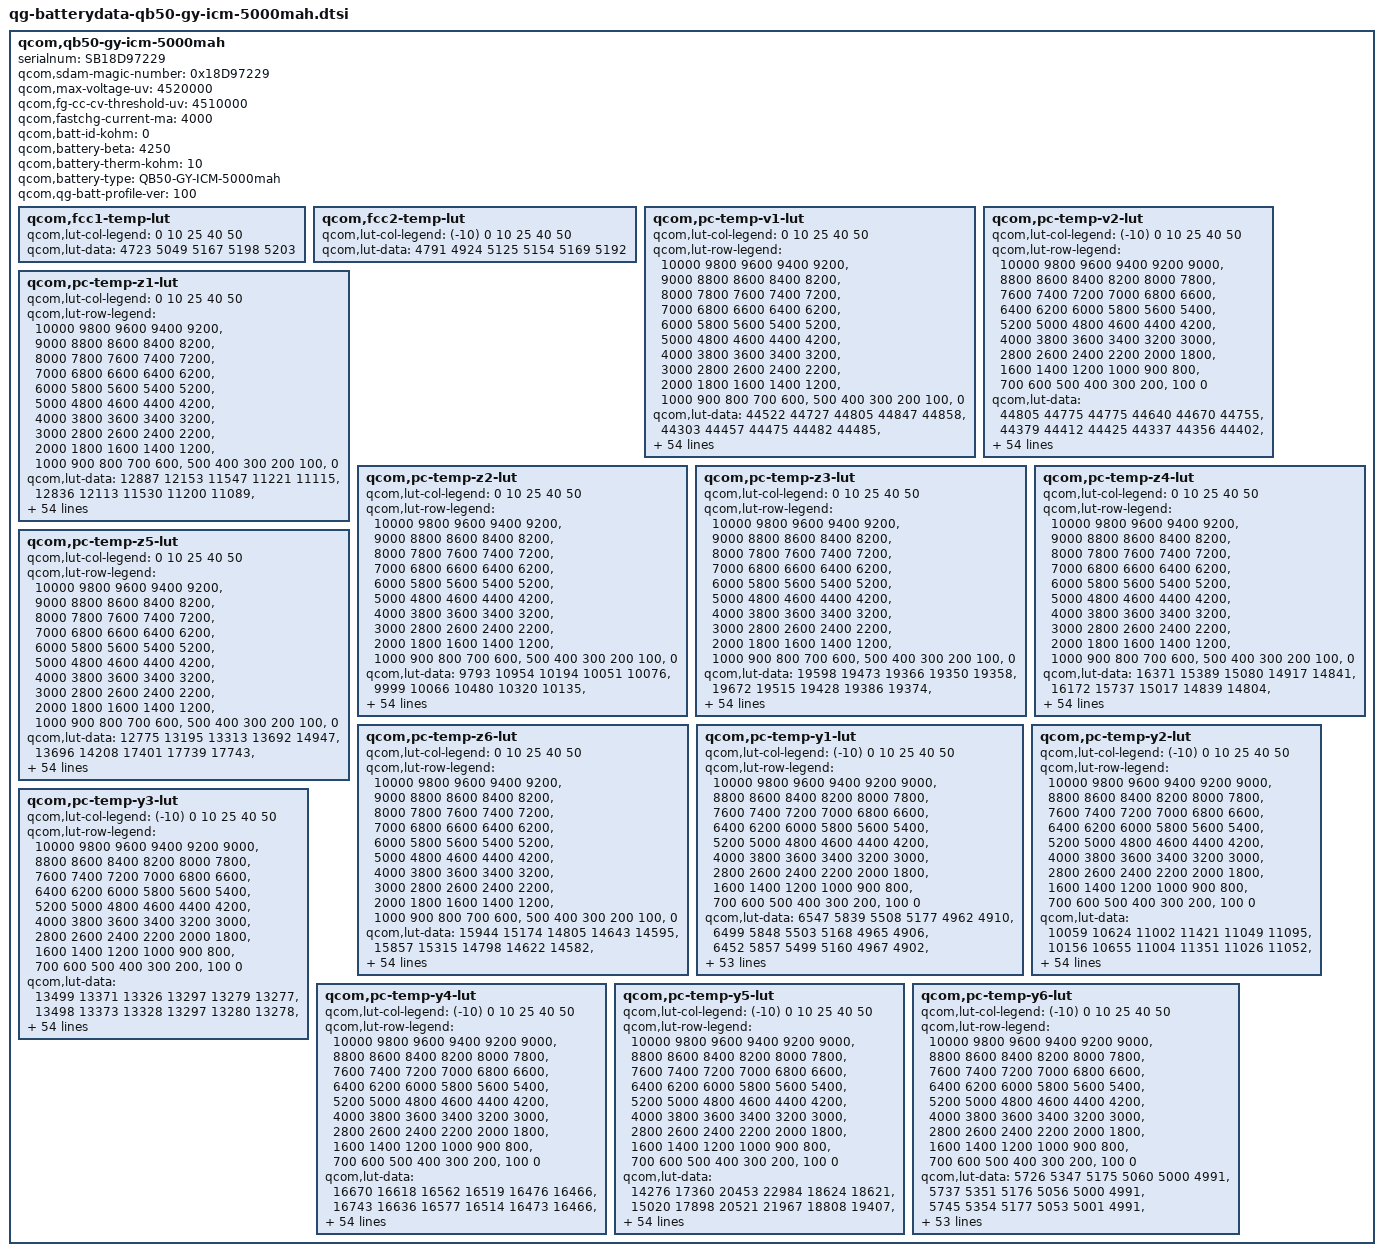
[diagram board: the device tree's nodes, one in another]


qcom,qb50-gy-icm-5000mah {
    /* 6658361_Heyuan_P652A_5000mAH_averaged_MasterSlave_Jun12th2023 */
    serialnum = "SB18D97229";
    qcom,sdam-magic-number = <0x18D97229>;
    qcom,max-voltage-uv = <4520000>;
    qcom,fg-cc-cv-threshold-uv = <4510000>;
    qcom,fastchg-current-ma = <4000>;
    qcom,batt-id-kohm = <0>;
    qcom,battery-beta = <4250>;
    qcom,battery-therm-kohm = <10>;
    qcom,battery-type = "QB50-GY-ICM-5000mah";
    qcom,qg-batt-profile-ver = <100>;

	qcom,fcc1-temp-lut {
		qcom,lut-col-legend = <0 10 25 40 50>;
		qcom,lut-data = <4723 5049 5167 5198 5203>;
	};

	qcom,fcc2-temp-lut {
		qcom,lut-col-legend = <(-10) 0 10 25 40 50>;
		qcom,lut-data = <4791 4924 5125 5154 5169 5192>;
	};

	qcom,pc-temp-v1-lut {
		qcom,lut-col-legend = <0 10 25 40 50>;
		qcom,lut-row-legend = <10000 9800 9600 9400 9200>,
			<9000 8800 8600 8400 8200>,
			<8000 7800 7600 7400 7200>,
			<7000 6800 6600 6400 6200>,
			<6000 5800 5600 5400 5200>,
			<5000 4800 4600 4400 4200>,
			<4000 3800 3600 3400 3200>,
			<3000 2800 2600 2400 2200>,
			<2000 1800 1600 1400 1200>,
			<1000 900 800 700 600>,
			<500 400 300 200 100>,
			<0>;
		qcom,lut-data = <44522 44727 44805 44847 44858>,
			<44303 44457 44475 44482 44485>,
			<44087 44233 44234 44237 44232>,
			<43876 44018 44024 44024 44019>,
			<43671 43803 43815 43814 43814>,
			<43461 43588 43593 43597 43600>,
			<43237 43361 43364 43374 43380>,
			<43005 43123 43127 43142 43151>,
			<42770 42878 42881 42899 42910>,
			<42528 42627 42631 42649 42662>,
			<42287 42372 42375 42396 42411>,
			<42052 42124 42119 42140 42157>,
			<41822 41878 41872 41890 41907>,
			<41596 41638 41633 41646 41660>,
			<41374 41402 41397 41408 41419>,
			<41157 41173 41160 41174 41183>,
			<40949 40956 40932 40947 40955>,
			<40748 40750 40719 40731 40737>,
			<40555 40550 40519 40523 40530>,
			<40367 40353 40326 40327 40332>,
			<40184 40161 40149 40153 40155>,
			<40008 39977 39953 39966 39969>,
			<39842 39801 39686 39701 39709>,
			<39679 39595 39399 39394 39406>,
			<39507 39302 39189 39188 39202>,
			<39328 39029 39021 39050 39069>,
			<39150 38883 38886 38932 38949>,
			<38970 38784 38781 38820 38819>,
			<38792 38693 38690 38717 38695>,
			<38661 38605 38598 38615 38588>,
			<38576 38526 38511 38517 38494>,
			<38507 38452 38430 38426 38408>,
			<38446 38383 38354 38345 38328>,
			<38389 38322 38284 38268 38252>,
			<38340 38268 38222 38198 38179>,
			<38295 38220 38164 38134 38109>,
			<38254 38178 38111 38069 38037>,
			<38215 38139 38063 38007 37964>,
			<38181 38090 38005 37936 37881>,
			<38144 38025 37922 37839 37776>,
			<38092 37944 37818 37726 37654>,
			<38021 37836 37703 37608 37531>,
			<37924 37701 37566 37481 37400>,
			<37788 37548 37403 37323 37231>,
			<37660 37380 37239 37167 37075>,
			<37496 37223 37118 37065 36992>,
			<37406 37171 37085 37031 36960>,
			<37315 37137 37057 37009 36935>,
			<37231 37101 37035 36989 36914>,
			<37158 37067 37000 36947 36867>,
			<37098 37027 36838 36740 36632>,
			<37041 36870 36419 36308 36189>,
			<36978 36431 35820 35721 35598>,
			<36882 35734 34989 34922 34783>,
			<36533 34686 33673 33672 33515>,
			<30000 30000 30000 30000 30000>;
	};

	qcom,pc-temp-v2-lut {
		qcom,lut-col-legend = <(-10) 0 10 25 40 50>;
		qcom,lut-row-legend = <10000 9800 9600 9400 9200 9000>,
			<8800 8600 8400 8200 8000 7800>,
			<7600 7400 7200 7000 6800 6600>,
			<6400 6200 6000 5800 5600 5400>,
			<5200 5000 4800 4600 4400 4200>,
			<4000 3800 3600 3400 3200 3000>,
			<2800 2600 2400 2200 2000 1800>,
			<1600 1400 1200 1000 900 800>,
			<700 600 500 400 300 200>,
			<100 0>;
		qcom,lut-data = <44805 44775 44775 44640 44670 44755>,
			<44379 44412 44425 44337 44356 44402>,
			<44020 44101 44121 44063 44075 44097>,
			<43748 43854 43874 43824 43834 43852>,
			<43548 43662 43673 43617 43628 43652>,
			<43364 43474 43469 43404 43416 43446>,
			<43161 43265 43244 43176 43189 43222>,
			<42955 43047 43012 42940 42954 42992>,
			<42744 42823 42773 42697 42711 42752>,
			<42527 42589 42525 42445 42460 42504>,
			<42302 42353 42277 42194 42209 42254>,
			<42073 42118 42027 41942 41958 42003>,
			<41838 41884 41777 41692 41709 41753>,
			<41596 41653 41533 41450 41467 41507>,
			<41342 41430 41293 41213 41230 41266>,
			<41080 41205 41061 40982 41000 41034>,
			<40827 40973 40839 40756 40774 40809>,
			<40579 40735 40620 40539 40557 40592>,
			<40338 40488 40404 40339 40352 40383>,
			<40103 40221 40186 40140 40152 40180>,
			<39873 39959 39941 39920 39961 39991>,
			<39656 39722 39662 39679 39776 39810>,
			<39452 39502 39405 39443 39566 39597>,
			<39257 39299 39188 39207 39293 39317>,
			<39069 39111 38994 38993 39037 39064>,
			<38888 38938 38828 38830 38865 38891>,
			<38718 38778 38682 38694 38728 38749>,
			<38556 38632 38548 38570 38604 38620>,
			<38406 38496 38420 38456 38491 38503>,
			<38287 38365 38302 38350 38388 38396>,
			<38194 38244 38193 38253 38295 38300>,
			<38114 38135 38092 38164 38210 38212>,
			<38038 38035 38001 38083 38132 38133>,
			<37969 37950 37918 38010 38062 38060>,
			<37901 37884 37845 37939 37987 37979>,
			<37832 37826 37785 37871 37904 37885>,
			<37765 37766 37732 37802 37815 37785>,
			<37696 37707 37677 37724 37717 37672>,
			<37627 37643 37621 37639 37611 37555>,
			<37556 37575 37554 37549 37509 37450>,
			<37482 37502 37451 37453 37414 37357>,
			<37406 37419 37323 37345 37311 37256>,
			<37328 37327 37181 37219 37192 37141>,
			<37249 37221 37022 37065 37040 36985>,
			<37165 37099 36844 36913 36915 36850>,
			<37075 36958 36683 36847 36869 36807>,
			<37025 36881 36623 36821 36857 36793>,
			<36968 36792 36543 36800 36843 36780>,
			<36911 36693 36413 36764 36816 36750>,
			<36858 36592 36252 36695 36741 36650>,
			<36801 36491 36007 36462 36452 36322>,
			<36629 36358 35443 35949 35930 35787>,
			<36422 36010 34906 35232 35242 35073>,
			<36366 35980 34417 34248 34233 34047>,
			<36694 36128 33625 32780 32977 32613>,
			<37268 36260 32241 29173 28356 28386>;
	};

	qcom,pc-temp-z1-lut {
		qcom,lut-col-legend = <0 10 25 40 50>;
		qcom,lut-row-legend = <10000 9800 9600 9400 9200>,
			<9000 8800 8600 8400 8200>,
			<8000 7800 7600 7400 7200>,
			<7000 6800 6600 6400 6200>,
			<6000 5800 5600 5400 5200>,
			<5000 4800 4600 4400 4200>,
			<4000 3800 3600 3400 3200>,
			<3000 2800 2600 2400 2200>,
			<2000 1800 1600 1400 1200>,
			<1000 900 800 700 600>,
			<500 400 300 200 100>,
			<0>;
		qcom,lut-data = <12887 12153 11547 11221 11115>,
			<12836 12113 11530 11200 11089>,
			<12794 12084 11502 11179 11076>,
			<12761 12059 11485 11167 11067>,
			<12733 12038 11470 11157 11060>,
			<12715 12018 11455 11147 11053>,
			<12706 11996 11441 11137 11046>,
			<12700 11970 11425 11129 11041>,
			<12687 11946 11409 11122 11037>,
			<12654 11924 11397 11116 11033>,
			<12614 11906 11389 11111 11030>,
			<12582 11895 11383 11108 11027>,
			<12548 11888 11379 11105 11024>,
			<12524 11882 11375 11103 11023>,
			<12510 11874 11373 11101 11022>,
			<12501 11868 11373 11100 11020>,
			<12494 11868 11372 11098 11019>,
			<12490 11871 11371 11098 11019>,
			<12487 11873 11369 11097 11019>,
			<12482 11872 11369 11097 11019>,
			<12475 11872 11372 11098 11019>,
			<12471 11874 11374 11099 11020>,
			<12481 11882 11374 11099 11019>,
			<12496 11889 11373 11099 11019>,
			<12501 11892 11374 11099 11018>,
			<12499 11896 11377 11101 11019>,
			<12498 11901 11381 11104 11021>,
			<12506 11908 11386 11107 11023>,
			<12523 11915 11391 11111 11027>,
			<12531 11921 11396 11115 11030>,
			<12529 11926 11401 11118 11033>,
			<12526 11932 11407 11122 11035>,
			<12529 11937 11414 11127 11038>,
			<12540 11944 11420 11132 11041>,
			<12550 11956 11424 11137 11045>,
			<12557 11968 11427 11143 11050>,
			<12565 11977 11433 11148 11054>,
			<12574 11984 11441 11152 11057>,
			<12588 11994 11449 11157 11061>,
			<12604 12008 11456 11162 11064>,
			<12625 12024 11462 11168 11068>,
			<12658 12043 11469 11173 11072>,
			<12688 12061 11477 11178 11075>,
			<12719 12068 11487 11184 11079>,
			<12710 12088 11501 11190 11082>,
			<12731 12105 11509 11196 11087>,
			<12742 12105 11509 11195 11086>,
			<12759 12099 11509 11197 11087>,
			<12759 12101 11512 11201 11090>,
			<12740 12105 11520 11206 11095>,
			<12732 12125 11523 11213 11100>,
			<12733 12134 11535 11220 11107>,
			<12740 12160 11541 11231 11117>,
			<12743 12179 11565 11246 11130>,
			<12743 12179 11565 11246 11130>,
			<12743 12179 11565 11246 11130>;
	};

	qcom,pc-temp-z2-lut {
		qcom,lut-col-legend = <0 10 25 40 50>;
		qcom,lut-row-legend = <10000 9800 9600 9400 9200>,
			<9000 8800 8600 8400 8200>,
			<8000 7800 7600 7400 7200>,
			<7000 6800 6600 6400 6200>,
			<6000 5800 5600 5400 5200>,
			<5000 4800 4600 4400 4200>,
			<4000 3800 3600 3400 3200>,
			<3000 2800 2600 2400 2200>,
			<2000 1800 1600 1400 1200>,
			<1000 900 800 700 600>,
			<500 400 300 200 100>,
			<0>;
		qcom,lut-data = <9793 10954 10194 10051 10076>,
			<9999 10066 10480 10320 10135>,
			<10135 10250 10606 10491 10349>,
			<10166 10372 10550 10471 10371>,
			<10176 10357 10483 10436 10382>,
			<10180 10323 10439 10396 10368>,
			<10178 10292 10401 10346 10311>,
			<10172 10260 10356 10302 10267>,
			<10165 10234 10301 10260 10240>,
			<10157 10212 10277 10235 10225>,
			<10146 10197 10281 10244 10228>,
			<10133 10197 10293 10263 10236>,
			<10117 10208 10473 10263 10241>,
			<10105 10222 11000 10232 10244>,
			<10100 10233 11182 10213 10246>,
			<10096 10248 10746 10237 10262>,
			<10097 10363 10337 10270 10285>,
			<10108 10707 10653 10261 10283>,
			<10123 10867 11354 10219 10252>,
			<10134 10639 11448 10200 10236>,
			<10144 10369 10824 10203 10224>,
			<10155 10348 10395 10215 10226>,
			<10167 10373 10487 10372 10376>,
			<10181 10400 10624 10678 10664>,
			<10199 10433 10610 10709 10705>,
			<10222 10458 10472 10418 10459>,
			<10246 10452 10405 10228 10290>,
			<10266 10430 10413 10243 10493>,
			<10286 10418 10425 10277 10790>,
			<10293 10414 10438 10343 10777>,
			<10288 10411 10460 10466 10553>,
			<10281 10408 10479 10511 10369>,
			<10278 10404 10495 10460 10243>,
			<10276 10403 10505 10391 10167>,
			<10275 10404 10509 10331 10163>,
			<10273 10406 10510 10267 10169>,
			<10272 10410 10510 10255 10187>,
			<10270 10414 10510 10273 10255>,
			<10265 10415 10514 10301 10328>,
			<10258 10409 10544 10395 10390>,
			<10245 10398 10577 10506 10438>,
			<10224 10381 10577 10506 10435>,
			<10204 10356 10563 10454 10406>,
			<10183 10315 10537 10418 10488>,
			<9927 10305 10524 10401 10565>,
			<9862 10299 10526 10406 10379>,
			<9827 10170 10398 10377 10354>,
			<9803 10110 10326 10377 10348>,
			<9775 10113 10361 10398 10377>,
			<9756 10100 10385 10460 10458>,
			<9748 10101 10377 10409 10383>,
			<9737 10032 10349 10237 10164>,
			<9694 9911 10186 10167 10088>,
			<9683 10032 10136 10104 10023>,
			<9683 10032 10136 10104 10023>,
			<9683 10032 10136 10104 10023>;
	};

	qcom,pc-temp-z3-lut {
		qcom,lut-col-legend = <0 10 25 40 50>;
		qcom,lut-row-legend = <10000 9800 9600 9400 9200>,
			<9000 8800 8600 8400 8200>,
			<8000 7800 7600 7400 7200>,
			<7000 6800 6600 6400 6200>,
			<6000 5800 5600 5400 5200>,
			<5000 4800 4600 4400 4200>,
			<4000 3800 3600 3400 3200>,
			<3000 2800 2600 2400 2200>,
			<2000 1800 1600 1400 1200>,
			<1000 900 800 700 600>,
			<500 400 300 200 100>,
			<0>;
		qcom,lut-data = <19598 19473 19366 19350 19358>,
			<19672 19515 19428 19386 19374>,
			<19720 19556 19468 19414 19398>,
			<19726 19578 19470 19421 19405>,
			<19724 19581 19472 19425 19408>,
			<19722 19582 19476 19428 19411>,
			<19716 19581 19481 19430 19414>,
			<19706 19576 19481 19431 19415>,
			<19703 19572 19478 19428 19413>,
			<19703 19570 19473 19423 19410>,
			<19703 19569 19466 19421 19408>,
			<19700 19563 19460 19419 19406>,
			<19692 19548 19465 19415 19404>,
			<19685 19536 19480 19408 19400>,
			<19683 19529 19485 19402 19397>,
			<19681 19524 19455 19398 19394>,
			<19677 19530 19428 19395 19391>,
			<19665 19553 19435 19391 19386>,
			<19652 19564 19453 19387 19381>,
			<19647 19537 19453 19382 19375>,
			<19644 19506 19423 19374 19369>,
			<19641 19503 19402 19368 19364>,
			<19638 19504 19417 19374 19368>,
			<19635 19507 19440 19389 19377>,
			<19636 19521 19439 19388 19377>,
			<19643 19536 19423 19365 19353>,
			<19652 19534 19411 19349 19337>,
			<19656 19525 19405 19350 19372>,
			<19659 19518 19401 19351 19422>,
			<19660 19514 19402 19359 19427>,
			<19654 19511 19405 19384 19416>,
			<19646 19512 19409 19395 19405>,
			<19641 19514 19416 19396 19395>,
			<19637 19515 19422 19395 19385>,
			<19634 19516 19423 19390 19374>,
			<19633 19516 19424 19380 19364>,
			<19632 19516 19423 19372 19356>,
			<19631 19515 19417 19365 19349>,
			<19629 19513 19411 19361 19346>,
			<19627 19508 19409 19362 19346>,
			<19622 19503 19407 19362 19346>,
			<19612 19500 19404 19362 19347>,
			<19601 19497 19401 19361 19351>,
			<19588 19490 19397 19360 19359>,
			<19402 19466 19390 19358 19364>,
			<19391 19445 19381 19348 19348>,
			<19394 19422 19371 19345 19342>,
			<19399 19356 19365 19337 19335>,
			<19400 19340 19349 19333 19328>,
			<19397 19331 19337 19326 19317>,
			<19389 19321 19339 19339 19333>,
			<19377 19333 19336 19362 19356>,
			<19382 19348 19358 19366 19356>,
			<19420 19503 19394 19357 19361>,
			<19420 19503 19394 19357 19361>,
			<19420 19503 19394 19357 19361>;
	};

	qcom,pc-temp-z4-lut {
		qcom,lut-col-legend = <0 10 25 40 50>;
		qcom,lut-row-legend = <10000 9800 9600 9400 9200>,
			<9000 8800 8600 8400 8200>,
			<8000 7800 7600 7400 7200>,
			<7000 6800 6600 6400 6200>,
			<6000 5800 5600 5400 5200>,
			<5000 4800 4600 4400 4200>,
			<4000 3800 3600 3400 3200>,
			<3000 2800 2600 2400 2200>,
			<2000 1800 1600 1400 1200>,
			<1000 900 800 700 600>,
			<500 400 300 200 100>,
			<0>;
		qcom,lut-data = <16371 15389 15080 14917 14841>,
			<16172 15737 15017 14839 14804>,
			<15980 15520 15159 14918 14869>,
			<15790 15297 15059 14887 14848>,
			<15597 15166 14950 14836 14808>,
			<15437 15060 14893 14805 14783>,
			<15320 14986 14848 14781 14764>,
			<15224 14931 14814 14761 14748>,
			<15143 14887 14787 14742 14733>,
			<15072 14849 14765 14728 14722>,
			<15012 14818 14750 14720 14716>,
			<14967 14796 14735 14714 14712>,
			<14931 14779 14706 14709 14708>,
			<14899 14766 14662 14706 14704>,
			<14867 14759 14649 14702 14700>,
			<14838 14752 14677 14697 14696>,
			<14819 14729 14703 14690 14691>,
			<14807 14679 14684 14686 14688>,
			<14797 14657 14642 14683 14686>,
			<14788 14686 14634 14679 14683>,
			<14781 14720 14656 14675 14677>,
			<14775 14722 14687 14672 14672>,
			<14769 14717 14722 14702 14701>,
			<14765 14718 14761 14771 14770>,
			<14765 14771 14793 14806 14802>,
			<14770 14828 14823 14825 14816>,
			<14780 14830 14834 14833 14821>,
			<14801 14822 14825 14823 14774>,
			<14836 14813 14809 14803 14704>,
			<14851 14803 14794 14775 14690>,
			<14850 14792 14776 14736 14688>,
			<14849 14781 14759 14709 14686>,
			<14847 14771 14740 14694 14683>,
			<14841 14763 14725 14685 14681>,
			<14835 14755 14714 14683 14679>,
			<14828 14749 14706 14682 14677>,
			<14821 14745 14705 14681 14677>,
			<14811 14741 14704 14682 14677>,
			<14796 14737 14704 14683 14678>,
			<14777 14732 14707 14690 14687>,
			<14760 14726 14711 14700 14700>,
			<14743 14718 14709 14699 14698>,
			<14729 14707 14701 14693 14688>,
			<14718 14694 14696 14694 14687>,
			<14852 14683 14686 14691 14683>,
			<14866 14680 14664 14669 14661>,
			<14868 14706 14667 14668 14660>,
			<14870 14776 14661 14661 14654>,
			<14876 14792 14664 14642 14638>,
			<14887 14799 14666 14633 14628>,
			<14902 14809 14675 14647 14649>,
			<14923 14800 14703 14649 14657>,
			<14926 14810 14690 14653 14666>,
			<14911 14683 14671 14667 14669>,
			<14911 14683 14671 14667 14669>,
			<14911 14683 14671 14667 14669>;
	};

	qcom,pc-temp-z5-lut {
		qcom,lut-col-legend = <0 10 25 40 50>;
		qcom,lut-row-legend = <10000 9800 9600 9400 9200>,
			<9000 8800 8600 8400 8200>,
			<8000 7800 7600 7400 7200>,
			<7000 6800 6600 6400 6200>,
			<6000 5800 5600 5400 5200>,
			<5000 4800 4600 4400 4200>,
			<4000 3800 3600 3400 3200>,
			<3000 2800 2600 2400 2200>,
			<2000 1800 1600 1400 1200>,
			<1000 900 800 700 600>,
			<500 400 300 200 100>,
			<0>;
		qcom,lut-data = <12775 13195 13313 13692 14947>,
			<13696 14208 17401 17739 17743>,
			<14403 15328 16944 18315 19312>,
			<14811 16225 17364 18961 20257>,
			<15073 16791 17968 20071 21398>,
			<15320 17231 18731 20830 22265>,
			<15588 17618 19632 21465 22969>,
			<15872 17938 20162 22140 23747>,
			<16261 18333 20455 22881 24707>,
			<16912 19112 20842 23652 25656>,
			<17599 19932 21495 24623 26442>,
			<18056 20237 22582 25599 27147>,
			<18406 20367 26608 25741 27768>,
			<18851 20545 35628 25324 28334>,
			<19766 20903 38639 25063 28999>,
			<20931 21555 31015 25873 30300>,
			<21680 24978 23830 27260 31816>,
			<22083 34687 30229 28228 32484>,
			<22505 39206 44387 29074 32678>,
			<23267 33106 46273 29306 32665>,
			<24425 25903 33513 28575 32509>,
			<25670 25769 24744 27871 32721>,
			<26844 28327 37556 31752 34473>,
			<28311 32207 56707 39954 37197>,
			<31041 42164 55444 40063 36269>,
			<37583 51183 37975 27277 24478>,
			<43560 48468 26805 18186 16414>,
			<46017 38465 23245 17024 23130>,
			<47773 32547 21412 16432 32992>,
			<48263 30079 21357 17222 34025>,
			<44856 28800 21513 20601 32627>,
			<39773 28992 21943 23795 31846>,
			<36993 29810 24290 27031 30973>,
			<35149 30790 27466 29284 29757>,
			<33999 32282 31228 29571 28506>,
			<33479 33868 34949 29696 27141>,
			<33130 35270 35620 29687 26662>,
			<33067 36542 35547 29420 26578>,
			<33864 36920 35417 29270 26568>,
			<34801 36968 35019 29885 26450>,
			<34742 36964 34270 30727 26278>,
			<33803 36551 32837 29612 26082>,
			<32782 35435 30531 26010 25749>,
			<30831 33146 29158 25705 30224>,
			<14355 28432 29052 26138 34985>,
			<12855 24832 30039 24511 27465>,
			<12837 19507 24484 22224 23082>,
			<12835 13283 22701 20691 20986>,
			<12738 12524 18678 22645 22548>,
			<12518 12204 16750 22846 21926>,
			<12199 11887 16549 25660 26959>,
			<11847 12213 14839 26111 26027>,
			<11822 12340 16708 24447 22151>,
			<12838 33735 24970 18663 20241>,
			<12838 33735 24970 18663 20241>,
			<12838 33735 24970 18663 20241>;
	};

	qcom,pc-temp-z6-lut {
		qcom,lut-col-legend = <0 10 25 40 50>;
		qcom,lut-row-legend = <10000 9800 9600 9400 9200>,
			<9000 8800 8600 8400 8200>,
			<8000 7800 7600 7400 7200>,
			<7000 6800 6600 6400 6200>,
			<6000 5800 5600 5400 5200>,
			<5000 4800 4600 4400 4200>,
			<4000 3800 3600 3400 3200>,
			<3000 2800 2600 2400 2200>,
			<2000 1800 1600 1400 1200>,
			<1000 900 800 700 600>,
			<500 400 300 200 100>,
			<0>;
		qcom,lut-data = <15944 15174 14805 14643 14595>,
			<15857 15315 14798 14622 14582>,
			<15766 15223 14872 14666 14620>,
			<15668 15123 14823 14654 14612>,
			<15561 15056 14770 14633 14596>,
			<15466 14998 14743 14620 14586>,
			<15392 14955 14722 14609 14579>,
			<15329 14920 14703 14599 14572>,
			<15277 14891 14686 14589 14564>,
			<15233 14868 14671 14580 14557>,
			<15195 14848 14658 14574 14553>,
			<15162 14829 14647 14569 14550>,
			<15133 14810 14637 14564 14546>,
			<15108 14797 14629 14558 14541>,
			<15084 14789 14622 14553 14537>,
			<15064 14782 14617 14548 14533>,
			<15048 14775 14612 14543 14529>,
			<15036 14768 14607 14539 14525>,
			<15026 14763 14601 14534 14521>,
			<15020 14760 14596 14529 14516>,
			<15016 14759 14592 14523 14509>,
			<15013 14759 14590 14518 14504>,
			<15012 14759 14610 14537 14520>,
			<15011 14761 14643 14575 14556>,
			<15012 14792 14654 14585 14565>,
			<15020 14825 14659 14582 14560>,
			<15031 14826 14660 14578 14555>,
			<15046 14821 14655 14573 14553>,
			<15065 14815 14647 14568 14551>,
			<15073 14810 14641 14563 14548>,
			<15071 14807 14636 14559 14543>,
			<15069 14804 14633 14555 14537>,
			<15067 14803 14630 14551 14531>,
			<15066 14802 14628 14546 14525>,
			<15064 14802 14626 14542 14519>,
			<15064 14801 14624 14538 14513>,
			<15064 14802 14622 14534 14509>,
			<15064 14803 14621 14531 14505>,
			<15064 14803 14620 14529 14504>,
			<15064 14803 14621 14533 14507>,
			<15063 14803 14624 14538 14513>,
			<15062 14803 14623 14538 14514>,
			<15062 14802 14621 14536 14512>,
			<15066 14801 14619 14537 14516>,
			<15047 14793 14615 14536 14518>,
			<15052 14787 14604 14523 14501>,
			<15057 14786 14601 14520 14497>,
			<15061 14783 14596 14514 14491>,
			<15065 14783 14590 14504 14481>,
			<15069 14783 14587 14497 14471>,
			<15072 14786 14595 14511 14490>,
			<15076 14795 14610 14527 14509>,
			<15082 14813 14621 14535 14516>,
			<15097 14848 14639 14540 14525>,
			<15097 14848 14639 14540 14525>,
			<15097 14848 14639 14540 14525>;
	};

	qcom,pc-temp-y1-lut {
		qcom,lut-col-legend = <(-10) 0 10 25 40 50>;
		qcom,lut-row-legend = <10000 9800 9600 9400 9200 9000>,
			<8800 8600 8400 8200 8000 7800>,
			<7600 7400 7200 7000 6800 6600>,
			<6400 6200 6000 5800 5600 5400>,
			<5200 5000 4800 4600 4400 4200>,
			<4000 3800 3600 3400 3200 3000>,
			<2800 2600 2400 2200 2000 1800>,
			<1600 1400 1200 1000 900 800>,
			<700 600 500 400 300 200>,
			<100 0>;
		qcom,lut-data = <6547 5839 5508 5177 4962 4910>,
			<6499 5848 5503 5168 4965 4906>,
			<6452 5857 5499 5160 4967 4902>,
			<6410 5865 5495 5152 4969 4898>,
			<6379 5870 5492 5145 4969 4894>,
			<6364 5872 5490 5139 4969 4890>,
			<6370 5870 5490 5135 4968 4886>,
			<6386 5866 5489 5130 4966 4882>,
			<6393 5864 5485 5124 4963 4879>,
			<6387 5854 5474 5117 4960 4877>,
			<6381 5846 5469 5113 4957 4875>,
			<6382 5847 5467 5109 4953 4872>,
			<6392 5848 5465 5107 4951 4871>,
			<6399 5848 5464 5105 4948 4869>,
			<6399 5846 5463 5103 4946 4868>,
			<6400 5844 5463 5101 4945 4868>,
			<6399 5841 5461 5098 4943 4867>,
			<6396 5835 5459 5096 4942 4867>,
			<6390 5833 5459 5097 4937 4867>,
			<6384 5839 5459 5099 4932 4867>,
			<6376 5847 5459 5099 4929 4867>,
			<6371 5848 5461 5100 4927 4867>,
			<6369 5849 5463 5100 4926 4868>,
			<6368 5850 5465 5104 4925 4869>,
			<6371 5846 5466 5107 4925 4870>,
			<6387 5842 5467 5110 4924 4870>,
			<6398 5845 5470 5112 4923 4870>,
			<6390 5857 5474 5115 4924 4871>,
			<6373 5863 5480 5118 4926 4873>,
			<6365 5854 5486 5121 4928 4875>,
			<6361 5842 5486 5124 4931 4878>,
			<6359 5841 5486 5127 4934 4880>,
			<6357 5844 5487 5131 4937 4883>,
			<6357 5847 5495 5136 4941 4885>,
			<6356 5849 5503 5141 4944 4887>,
			<6355 5850 5508 5146 4947 4888>,
			<6354 5854 5512 5150 4949 4889>,
			<6353 5861 5516 5154 4951 4891>,
			<6351 5866 5521 5157 4954 4892>,
			<6348 5867 5526 5160 4956 4894>,
			<6339 5867 5532 5163 4958 4896>,
			<6322 5868 5535 5167 4960 4898>,
			<6317 5874 5535 5171 4962 4899>,
			<6328 5872 5537 5177 4965 4902>,
			<6349 5853 5532 5185 4969 4906>,
			<6406 5832 5528 5192 4974 4908>,
			<6441 5864 5526 5193 4980 4908>,
			<6489 5887 5556 5199 4974 4907>,
			<6515 5906 5596 5205 4975 4909>,
			<6510 5943 5615 5211 4974 4910>,
			<6574 5984 5545 5218 4976 4913>,
			<6604 6001 5437 5242 4984 4919>,
			<6602 5883 5437 5255 4993 4928>,
			<6505 5812 5437 5276 5007 4944>,
			<6505 5812 5437 5276 5007 4944>,
			<6505 5812 5437 5276 5007 4944>;
	};

	qcom,pc-temp-y2-lut {
		qcom,lut-col-legend = <(-10) 0 10 25 40 50>;
		qcom,lut-row-legend = <10000 9800 9600 9400 9200 9000>,
			<8800 8600 8400 8200 8000 7800>,
			<7600 7400 7200 7000 6800 6600>,
			<6400 6200 6000 5800 5600 5400>,
			<5200 5000 4800 4600 4400 4200>,
			<4000 3800 3600 3400 3200 3000>,
			<2800 2600 2400 2200 2000 1800>,
			<1600 1400 1200 1000 900 800>,
			<700 600 500 400 300 200>,
			<100 0>;
		qcom,lut-data = <10059 10624 11002 11421 11049 11095>,
			<10156 10655 11004 11351 11026 11052>,
			<10270 10693 10999 11265 11001 11008>,
			<10384 10730 10988 11180 10974 10964>,
			<10483 10762 10974 11110 10944 10923>,
			<10549 10783 10957 11069 10913 10886>,
			<10579 10792 10932 11047 10876 10849>,
			<10598 10799 10909 11030 10842 10816>,
			<10618 10808 10899 11011 10817 10792>,
			<10644 10819 10892 10992 10795 10773>,
			<10670 10832 10891 10979 10788 10760>,
			<10693 10846 10903 10969 10788 10751>,
			<10716 10862 10924 10964 10789 10743>,
			<10729 10882 10950 10976 10826 10732>,
			<10732 10911 10987 11007 10890 10723>,
			<10734 10943 11022 11042 10906 10726>,
			<10734 10979 11055 11086 10904 10748>,
			<10727 11016 11092 11137 10905 10767>,
			<10715 11028 11147 11212 10934 10777>,
			<10700 11014 11202 11282 10995 10789>,
			<10677 10996 11204 11302 11120 10870>,
			<10650 10986 11164 11309 11348 11051>,
			<10618 10978 11136 11310 11425 11105>,
			<10581 10967 11135 11267 11271 11060>,
			<10546 10943 11137 11221 11118 11023>,
			<10514 10911 11134 11229 11120 11043>,
			<10471 10878 11123 11263 11154 11085>,
			<10350 10841 11108 11289 11164 11114>,
			<10162 10801 11085 11308 11178 11146>,
			<10033 10757 11053 11325 11196 11189>,
			<9870 10710 11008 11342 11227 11267>,
			<9730 10663 10946 11361 11272 11352>,
			<9701 10614 10889 11371 11319 11409>,
			<9688 10564 10840 11382 11374 11456>,
			<9681 10522 10793 11385 11407 11465>,
			<9675 10475 10745 11372 11392 11408>,
			<9671 10358 10695 11348 11354 11348>,
			<9668 10050 10642 11310 11289 11298>,
			<9666 9809 10589 11240 11179 11233>,
			<9665 9743 10508 11175 11142 11210>,
			<9663 9703 10260 11078 11156 11202>,
			<9661 9684 9976 11007 11149 11169>,
			<9659 9674 9820 10975 11103 11111>,
			<9658 9667 9725 10842 11098 11103>,
			<9656 9661 9681 10750 11006 11011>,
			<9654 9656 9658 10697 10886 10833>,
			<9653 9654 9654 10595 10943 10812>,
			<9651 9652 9652 10754 10973 10834>,
			<9650 9651 9650 10734 11016 10910>,
			<9650 9650 9650 10743 11049 10833>,
			<9649 9650 9650 10580 10817 10745>,
			<9649 9649 9650 10107 10755 10679>,
			<9649 9650 9650 9778 10685 10588>,
			<9650 9650 9650 9662 10583 10441>,
			<9650 9650 9650 9662 10583 10441>,
			<9650 9650 9650 9662 10583 10441>;
	};

	qcom,pc-temp-y3-lut {
		qcom,lut-col-legend = <(-10) 0 10 25 40 50>;
		qcom,lut-row-legend = <10000 9800 9600 9400 9200 9000>,
			<8800 8600 8400 8200 8000 7800>,
			<7600 7400 7200 7000 6800 6600>,
			<6400 6200 6000 5800 5600 5400>,
			<5200 5000 4800 4600 4400 4200>,
			<4000 3800 3600 3400 3200 3000>,
			<2800 2600 2400 2200 2000 1800>,
			<1600 1400 1200 1000 900 800>,
			<700 600 500 400 300 200>,
			<100 0>;
		qcom,lut-data = <13499 13371 13326 13297 13279 13277>,
			<13498 13373 13328 13297 13280 13278>,
			<13496 13376 13330 13297 13282 13280>,
			<13493 13380 13332 13297 13283 13281>,
			<13490 13384 13333 13297 13284 13282>,
			<13488 13385 13334 13298 13285 13282>,
			<13486 13385 13335 13299 13286 13283>,
			<13484 13385 13336 13300 13286 13283>,
			<13482 13384 13338 13300 13287 13284>,
			<13481 13383 13339 13300 13288 13285>,
			<13478 13381 13340 13301 13289 13286>,
			<13476 13379 13339 13301 13289 13286>,
			<13473 13377 13339 13301 13290 13287>,
			<13469 13376 13338 13303 13292 13287>,
			<13463 13377 13336 13306 13295 13287>,
			<13455 13377 13335 13307 13296 13288>,
			<13449 13377 13334 13307 13296 13290>,
			<13444 13376 13334 13306 13296 13291>,
			<13439 13374 13334 13305 13297 13292>,
			<13435 13369 13335 13304 13298 13292>,
			<13431 13362 13334 13303 13298 13292>,
			<13430 13359 13329 13302 13297 13293>,
			<13429 13356 13323 13300 13295 13292>,
			<13429 13354 13320 13296 13290 13286>,
			<13428 13351 13317 13292 13285 13281>,
			<13427 13349 13317 13291 13283 13280>,
			<13426 13349 13316 13290 13282 13280>,
			<13420 13349 13316 13290 13281 13279>,
			<13410 13349 13315 13290 13280 13279>,
			<13409 13350 13314 13290 13279 13279>,
			<13427 13350 13314 13290 13279 13279>,
			<13455 13349 13315 13290 13279 13279>,
			<13482 13346 13315 13290 13279 13279>,
			<13514 13343 13316 13291 13281 13279>,
			<13554 13347 13318 13291 13282 13279>,
			<13607 13355 13320 13292 13282 13279>,
			<13674 13364 13324 13292 13281 13280>,
			<13752 13376 13329 13292 13281 13279>,
			<13849 13392 13337 13292 13281 13279>,
			<13964 13419 13344 13292 13281 13279>,
			<14097 13460 13348 13292 13282 13280>,
			<14258 13515 13354 13292 13282 13282>,
			<14465 13596 13374 13293 13282 13283>,
			<14736 13728 13418 13291 13280 13280>,
			<15226 13998 13501 13288 13278 13276>,
			<16678 14671 14065 13295 13285 13284>,
			<17854 15343 15243 13296 13288 13286>,
			<19938 16670 17934 13303 13292 13290>,
			<22979 19375 25268 13309 13294 13292>,
			<28088 25285 49015 13318 13294 13290>,
			<38490 39355 65535 13322 13289 13285>,
			<60218 65535 65535 13333 13289 13286>,
			<65535 65535 65535 13420 13293 13291>,
			<65535 65535 65535 14570 13299 13302>,
			<65535 65535 65535 14570 13299 13302>,
			<65535 65535 65535 14570 13299 13302>;
	};

	qcom,pc-temp-y4-lut {
		qcom,lut-col-legend = <(-10) 0 10 25 40 50>;
		qcom,lut-row-legend = <10000 9800 9600 9400 9200 9000>,
			<8800 8600 8400 8200 8000 7800>,
			<7600 7400 7200 7000 6800 6600>,
			<6400 6200 6000 5800 5600 5400>,
			<5200 5000 4800 4600 4400 4200>,
			<4000 3800 3600 3400 3200 3000>,
			<2800 2600 2400 2200 2000 1800>,
			<1600 1400 1200 1000 900 800>,
			<700 600 500 400 300 200>,
			<100 0>;
		qcom,lut-data = <16670 16618 16562 16519 16476 16466>,
			<16743 16636 16577 16514 16473 16466>,
			<16832 16671 16589 16509 16470 16465>,
			<16923 16711 16599 16504 16467 16465>,
			<17002 16745 16604 16500 16466 16465>,
			<17053 16761 16606 16497 16465 16464>,
			<17076 16763 16602 16495 16466 16464>,
			<17091 16764 16597 16494 16467 16464>,
			<17095 16764 16594 16495 16469 16464>,
			<17092 16765 16591 16497 16471 16465>,
			<17085 16767 16591 16500 16473 16465>,
			<17077 16773 16595 16506 16476 16467>,
			<17061 16785 16604 16512 16480 16468>,
			<17042 16795 16616 16517 16482 16471>,
			<17017 16806 16636 16522 16484 16475>,
			<16987 16813 16658 16531 16488 16478>,
			<16958 16810 16686 16548 16497 16481>,
			<16931 16799 16704 16570 16507 16485>,
			<16902 16782 16708 16603 16518 16491>,
			<16872 16746 16710 16633 16532 16501>,
			<16839 16703 16700 16631 16555 16522>,
			<16809 16673 16638 16604 16588 16553>,
			<16780 16647 16583 16570 16596 16558>,
			<16753 16627 16552 16521 16534 16513>,
			<16725 16611 16531 16483 16473 16473>,
			<16693 16598 16523 16480 16467 16466>,
			<16675 16587 16519 16479 16464 16462>,
			<16680 16578 16517 16479 16465 16463>,
			<16690 16570 16516 16483 16471 16466>,
			<16698 16558 16515 16488 16480 16472>,
			<16711 16549 16513 16494 16488 16478>,
			<16725 16549 16510 16500 16498 16486>,
			<16734 16555 16508 16508 16506 16496>,
			<16741 16562 16506 16516 16515 16509>,
			<16748 16568 16505 16520 16518 16512>,
			<16756 16575 16510 16520 16515 16510>,
			<16763 16587 16522 16519 16509 16506>,
			<16768 16614 16535 16514 16498 16495>,
			<16772 16639 16551 16501 16481 16480>,
			<16775 16655 16565 16494 16476 16478>,
			<16775 16668 16572 16492 16477 16482>,
			<16775 16677 16578 16492 16479 16488>,
			<16775 16682 16583 16496 16481 16490>,
			<16773 16685 16591 16490 16462 16466>,
			<16779 16687 16588 16473 16445 16442>,
			<16980 16688 16620 16483 16457 16456>,
			<17137 16703 16667 16498 16476 16487>,
			<17385 16820 17010 16514 16510 16529>,
			<17705 17189 18670 16541 16549 16569>,
			<18150 18149 26796 16577 16568 16569>,
			<19120 21475 51721 16577 16509 16501>,
			<19453 35972 46528 16573 16478 16483>,
			<16612 27251 17019 16657 16480 16482>,
			<16727 65535 65535 17091 16493 16493>,
			<16727 65535 65535 17091 16493 16493>,
			<16727 65535 65535 17091 16493 16493>;
	};

	qcom,pc-temp-y5-lut {
		qcom,lut-col-legend = <(-10) 0 10 25 40 50>;
		qcom,lut-row-legend = <10000 9800 9600 9400 9200 9000>,
			<8800 8600 8400 8200 8000 7800>,
			<7600 7400 7200 7000 6800 6600>,
			<6400 6200 6000 5800 5600 5400>,
			<5200 5000 4800 4600 4400 4200>,
			<4000 3800 3600 3400 3200 3000>,
			<2800 2600 2400 2200 2000 1800>,
			<1600 1400 1200 1000 900 800>,
			<700 600 500 400 300 200>,
			<100 0>;
		qcom,lut-data = <14276 17360 20453 22984 18624 18621>,
			<15020 17898 20521 21967 18808 19407>,
			<15741 18244 20456 20943 18858 20063>,
			<16416 18439 20288 19980 18801 20559>,
			<17024 18526 20042 19145 18663 20860>,
			<17544 18547 19746 18502 18461 20924>,
			<17956 18459 19334 18010 17946 20436>,
			<18301 18244 18885 17590 17322 19828>,
			<18670 17999 18550 17127 16911 19529>,
			<19091 17641 18273 16555 16574 19189>,
			<19522 17387 17908 16088 16251 18864>,
			<19971 17363 17323 15466 15868 18373>,
			<20488 17394 16724 15045 15646 17819>,
			<20757 17523 16233 15198 16021 17138>,
			<20701 18321 15807 15504 16695 16508>,
			<20600 19463 15760 15496 16696 16513>,
			<20591 20772 16353 15030 15945 16941>,
			<20814 22282 17348 14732 15404 17140>,
			<21111 22781 19645 15045 15254 16429>,
			<21337 22603 22665 15820 15172 15639>,
			<21557 22414 23632 17748 15681 15665>,
			<21751 22458 23956 22057 17656 15985>,
			<21949 22633 24064 23916 19503 16644>,
			<22099 22707 23553 22959 21301 19048>,
			<22010 22451 22864 21726 22443 20821>,
			<21307 22120 22903 21177 21721 20471>,
			<20242 22026 23383 20808 19782 19636>,
			<17929 21979 23644 20581 18283 18767>,
			<14713 21896 22976 20393 16952 17386>,
			<13487 21501 22183 20294 16303 16680>,
			<13234 20745 22032 20429 16338 16604>,
			<13109 19385 21739 20785 16438 16575>,
			<13122 16641 21365 21232 16865 16699>,
			<13197 15090 20685 21996 18289 17150>,
			<13275 15392 20202 22872 19588 17801>,
			<13334 15862 20260 24074 20604 19103>,
			<13396 15851 20453 25108 21349 20360>,
			<13483 15203 20785 24991 21629 21070>,
			<13617 14668 21732 24105 21797 21629>,
			<13702 14560 22331 23207 21817 22074>,
			<13705 14495 20014 21787 21615 22531>,
			<13704 14413 16814 20665 21260 22790>,
			<13693 14310 15250 20061 20779 23389>,
			<13558 14191 14405 19013 20799 25578>,
			<13228 13983 13991 17186 18369 18843>,
			<11649 13574 13386 18574 18475 19408>,
			<10960 13074 13221 16874 18592 17373>,
			<10409 11790 11058 17937 18314 16604>,
			<10134 10497 9661 17923 17345 16040>,
			<10091 9828 9177 18778 16794 15125>,
			<10163 9407 9049 18489 16146 15540>,
			<10553 9137 14798 16617 17830 15525>,
			<31033 18310 22488 14317 18370 16138>,
			<25222 15702 13837 12785 20905 21779>,
			<25222 15702 13837 12785 20905 21779>,
			<25222 15702 13837 12785 20905 21779>;
	};

	qcom,pc-temp-y6-lut {
		qcom,lut-col-legend = <(-10) 0 10 25 40 50>;
		qcom,lut-row-legend = <10000 9800 9600 9400 9200 9000>,
			<8800 8600 8400 8200 8000 7800>,
			<7600 7400 7200 7000 6800 6600>,
			<6400 6200 6000 5800 5600 5400>,
			<5200 5000 4800 4600 4400 4200>,
			<4000 3800 3600 3400 3200 3000>,
			<2800 2600 2400 2200 2000 1800>,
			<1600 1400 1200 1000 900 800>,
			<700 600 500 400 300 200>,
			<100 0>;
		qcom,lut-data = <5726 5347 5175 5060 5000 4991>,
			<5737 5351 5176 5056 5000 4991>,
			<5745 5354 5177 5053 5001 4991>,
			<5749 5355 5176 5050 5001 4991>,
			<5751 5356 5174 5047 5002 4992>,
			<5752 5356 5171 5045 5002 4992>,
			<5751 5353 5168 5044 5003 4992>,
			<5747 5347 5164 5043 5004 4992>,
			<5742 5342 5161 5042 5004 4993>,
			<5737 5336 5158 5042 5005 4993>,
			<5729 5333 5157 5042 5006 4994>,
			<5721 5331 5157 5043 5007 4994>,
			<5712 5329 5157 5044 5008 4995>,
			<5702 5329 5158 5046 5010 4996>,
			<5689 5330 5161 5049 5013 4997>,
			<5675 5331 5165 5053 5015 4998>,
			<5662 5330 5172 5057 5017 5001>,
			<5650 5325 5176 5062 5020 5003>,
			<5640 5319 5178 5070 5023 5005>,
			<5630 5305 5179 5078 5027 5008>,
			<5620 5289 5175 5077 5033 5014>,
			<5614 5279 5154 5068 5040 5023>,
			<5610 5270 5135 5057 5042 5024>,
			<5608 5265 5125 5040 5020 5006>,
			<5608 5261 5118 5027 4998 4991>,
			<5610 5259 5117 5026 4995 4988>,
			<5613 5259 5117 5026 4993 4986>,
			<5620 5261 5117 5026 4993 4986>,
			<5632 5263 5119 5028 4994 4987>,
			<5649 5266 5120 5030 4996 4989>,
			<5676 5270 5122 5032 4999 4991>,
			<5711 5276 5125 5035 5002 4993>,
			<5749 5286 5129 5039 5005 4997>,
			<5793 5300 5133 5042 5009 5001>,
			<5843 5319 5140 5045 5011 5002>,
			<5900 5345 5149 5047 5010 5001>,
			<5965 5376 5163 5048 5009 5001>,
			<6040 5414 5181 5048 5006 4998>,
			<6126 5460 5205 5045 5001 4993>,
			<6225 5512 5233 5044 5000 4993>,
			<6339 5574 5262 5045 5001 4996>,
			<6473 5649 5297 5047 5003 4999>,
			<6643 5742 5350 5052 5004 5000>,
			<6860 5880 5437 5051 4997 4991>,
			<7258 6123 5567 5046 4991 4983>,
			<8490 6657 6108 5060 5001 4993>,
			<9450 7168 6990 5068 5009 5004>,
			<11026 8195 9056 5083 5022 5018>,
			<13260 10256 14651 5100 5034 5031>,
			<16886 14630 32988 5125 5040 5030>,
			<24240 25115 65535 5141 5019 5008>,
			<38987 54089 65535 5183 5011 5005>,
			<65535 65535 65535 5384 5017 5009>,
			<65535 65535 65535 6508 5027 5023>,
			<65535 65535 65535 6508 5027 5023>,
			<65535 65535 65535 6508 5027 5023>;
	};

};
